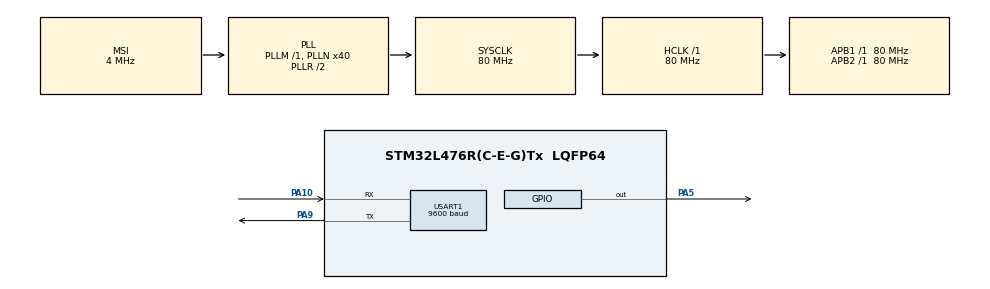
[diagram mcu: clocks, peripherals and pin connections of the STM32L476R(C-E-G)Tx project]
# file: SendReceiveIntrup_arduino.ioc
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Mcu.Family=STM32L4
Mcu.Name=STM32L476R(C-E-G)Tx
Mcu.Package=LQFP64
NVIC.PriorityGroup=NVIC_PRIORITYGROUP_4
NVIC.USART1_IRQn=true\:0\:0\:false\:false\:true\:true\:true\:true
PA10.Mode=Asynchronous
PA10.Signal=USART1_RX
PA13\ (JTMS-SWDIO).Mode=Serial_Wire
PA13\ (JTMS-SWDIO).Signal=SYS_JTMS-SWDIO
PA14\ (JTCK-SWCLK).Mode=Serial_Wire
PA14\ (JTCK-SWCLK).Signal=SYS_JTCK-SWCLK
PA5.Signal=GPIO_Output
PA9.Mode=Asynchronous
PA9.Signal=USART1_TX
PH0-OSC_IN\ (PH0).Mode=HSE-External-Oscillator
PH0-OSC_IN\ (PH0).Signal=RCC_OSC_IN
PH1-OSC_OUT\ (PH1).Mode=HSE-External-Oscillator
PH1-OSC_OUT\ (PH1).Signal=RCC_OSC_OUT
ProjectManager.HeapSize=0x200
ProjectManager.StackSize=0x400
ProjectManager.TargetToolchain=STM32CubeIDE
RCC.AHBFreq_Value=80000000
RCC.APB1Freq_Value=80000000
RCC.APB1TimFreq_Value=80000000
RCC.APB2Freq_Value=80000000
RCC.APB2TimFreq_Value=80000000
RCC.CortexFreq_Value=80000000
RCC.HCLKFreq_Value=80000000
RCC.HSE_VALUE=8000000
RCC.HSI_VALUE=16000000
RCC.LSE_VALUE=32768
RCC.MSI_VALUE=4000000
RCC.PLLN=40
RCC.SYSCLKFreq_VALUE=80000000
RCC.SYSCLKSource=RCC_SYSCLKSOURCE_PLLCLK
RCC.VCOOutputFreq_Value=160000000
USART1.BaudRate=9600
USART1.VirtualMode-Asynchronous=VM_ASYNC
board=custom

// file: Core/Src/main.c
/* USER CODE BEGIN Header */
/**
  ******************************************************************************
  * @file           : main.c
  * @brief          : Main program body
  ******************************************************************************
  * @attention
  *
  * Copyright (c) 2025 STMicroelectronics.
  * All rights reserved.
  *
  * This software is licensed under terms that can be found in the LICENSE file
  * in the root directory of this software component.
  * If no LICENSE file comes with this software, it is provided AS-IS.
  *
  ******************************************************************************
  */
/* USER CODE END Header */
#include "main.h"

/* USER CODE BEGIN Includes */
#include "stdio.h"
#include "string.h"
/* USER CODE END Includes */

UART_HandleTypeDef huart1;

/* USER CODE BEGIN PV */
uint8_t rx_buffer[50];          // Buffer for received data
volatile uint8_t rx_complete = 0; // Flag for reception complete
uint8_t tx_buffer[] = "REQUEST_DATA\n"; // Message to send
/* USER CODE END PV */

void SystemClock_Config(void);
static void MX_GPIO_Init(void);
static void MX_USART1_UART_Init(void);

/* USER CODE BEGIN 0 */
/* Redirect printf to SWV */
int _write(int file, char *ptr, int len) {
  for (int i = 0; i < len; i++) {
    ITM_SendChar(*ptr++);
  }
  return len;
}

/* UART Receive Callback */
/* UART Receive Callback */
void HAL_UART_RxCpltCallback(UART_HandleTypeDef *huart) {
  if (huart->Instance == USART1) {
    rx_complete = 1; // Set flag when reception is complete
    printf("Interrupt triggered, raw data: %s\n", rx_buffer); // Debug raw buffer
  }
}
/* UART Error Callback */
void HAL_UART_ErrorCallback(UART_HandleTypeDef *huart) {
  if (huart->Instance == USART1) {
    printf("UART Error: %lu\n", huart->ErrorCode); // Report error code
  }
}
/* USER CODE END 0 */

int main(void)
{

  /* MCU Configuration--------------------------------------------------------*/

  /* Reset of all peripherals, Initializes the Flash interface and the Systick. */
  HAL_Init();

  /* Configure the system clock */
  SystemClock_Config();

  /* Initialize all configured peripherals */
  MX_GPIO_Init();
  MX_USART1_UART_Init();

  /* Infinite loop */
  /* USER CODE BEGIN WHILE */
  HAL_UART_Receive_IT(&huart1, rx_buffer, 28); // "RESPONSE: Hello from Arduino\n" = 28 bytes

    /* Infinite loop */
    while (1) {
      /* Send request to Arduino every 2 seconds */
      HAL_UART_Transmit_IT(&huart1, tx_buffer, strlen((char*)tx_buffer));
      printf("Sent to Arduino: %s", tx_buffer);

      /* Check if data was received */
      if (rx_complete) {
        rx_buffer[49] = '\0'; // Ensure null termination
        printf("Received from Arduino: %s\n", rx_buffer);
        rx_complete = 0; // Reset flag

        /* Restart reception for next message */
        HAL_UART_Receive_IT(&huart1, rx_buffer, 28);
      } else {
        printf("Waiting for response...\n"); // Debug: no data yet
      }

      HAL_Delay(2000); // Wait 2 seconds before next request
    }
}

void SystemClock_Config(void)
{
  RCC_OscInitTypeDef RCC_OscInitStruct = {0};
  RCC_ClkInitTypeDef RCC_ClkInitStruct = {0};

  /** Configure the main internal regulator output voltage
  */
  if (HAL_PWREx_ControlVoltageScaling(PWR_REGULATOR_VOLTAGE_SCALE1) != HAL_OK)
  {
    Error_Handler();
  }

  /** Initializes the RCC Oscillators according to the specified parameters
  * in the RCC_OscInitTypeDef structure.
  */
  RCC_OscInitStruct.OscillatorType = RCC_OSCILLATORTYPE_MSI;
  RCC_OscInitStruct.MSIState = RCC_MSI_ON;
  RCC_OscInitStruct.MSICalibrationValue = 0;
  RCC_OscInitStruct.MSIClockRange = RCC_MSIRANGE_6;
  RCC_OscInitStruct.PLL.PLLState = RCC_PLL_ON;
  RCC_OscInitStruct.PLL.PLLSource = RCC_PLLSOURCE_MSI;
  RCC_OscInitStruct.PLL.PLLM = 1;
  RCC_OscInitStruct.PLL.PLLN = 40;
  RCC_OscInitStruct.PLL.PLLP = RCC_PLLP_DIV7;
  RCC_OscInitStruct.PLL.PLLQ = RCC_PLLQ_DIV2;
  RCC_OscInitStruct.PLL.PLLR = RCC_PLLR_DIV2;
  if (HAL_RCC_OscConfig(&RCC_OscInitStruct) != HAL_OK)
  {
    Error_Handler();
  }

  /** Initializes the CPU, AHB and APB buses clocks
  */
  RCC_ClkInitStruct.ClockType = RCC_CLOCKTYPE_HCLK|RCC_CLOCKTYPE_SYSCLK
                              |RCC_CLOCKTYPE_PCLK1|RCC_CLOCKTYPE_PCLK2;
  RCC_ClkInitStruct.SYSCLKSource = RCC_SYSCLKSOURCE_PLLCLK;
  RCC_ClkInitStruct.AHBCLKDivider = RCC_SYSCLK_DIV1;
  RCC_ClkInitStruct.APB1CLKDivider = RCC_HCLK_DIV1;
  RCC_ClkInitStruct.APB2CLKDivider = RCC_HCLK_DIV1;

  if (HAL_RCC_ClockConfig(&RCC_ClkInitStruct, FLASH_LATENCY_4) != HAL_OK)
  {
    Error_Handler();
  }
}

static void MX_USART1_UART_Init(void)
{

  huart1.Instance = USART1;
  huart1.Init.BaudRate = 9600;
  huart1.Init.WordLength = UART_WORDLENGTH_8B;
  huart1.Init.StopBits = UART_STOPBITS_1;
  huart1.Init.Parity = UART_PARITY_NONE;
  huart1.Init.Mode = UART_MODE_TX_RX;
  huart1.Init.HwFlowCtl = UART_HWCONTROL_NONE;
  huart1.Init.OverSampling = UART_OVERSAMPLING_16;
  huart1.Init.OneBitSampling = UART_ONE_BIT_SAMPLE_DISABLE;
  huart1.AdvancedInit.AdvFeatureInit = UART_ADVFEATURE_NO_INIT;
  if (HAL_UART_Init(&huart1) != HAL_OK)
  {
    Error_Handler();
  }

}

static void MX_GPIO_Init(void)
{
  GPIO_InitTypeDef GPIO_InitStruct = {0};

  /* GPIO Ports Clock Enable */
  __HAL_RCC_GPIOH_CLK_ENABLE();
  __HAL_RCC_GPIOA_CLK_ENABLE();

  /*Configure GPIO pin Output Level */
  HAL_GPIO_WritePin(GPIOA, GPIO_PIN_5, GPIO_PIN_RESET);

  /*Configure GPIO pin : PA5 */
  GPIO_InitStruct.Pin = GPIO_PIN_5;
  GPIO_InitStruct.Mode = GPIO_MODE_OUTPUT_PP;
  GPIO_InitStruct.Pull = GPIO_NOPULL;
  GPIO_InitStruct.Speed = GPIO_SPEED_FREQ_LOW;
  HAL_GPIO_Init(GPIOA, &GPIO_InitStruct);

}

void Error_Handler(void)
{
  __disable_irq();
  while (1)
  {
  }
}
